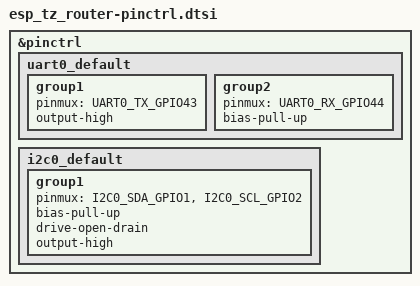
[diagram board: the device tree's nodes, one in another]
/*
 * Copyright (c) 2025 Espressif Systems (Shanghai) Co., Ltd.
 *
 * SPDX-License-Identifier: Apache-2.0
 */

#include <zephyr/dt-bindings/pinctrl/esp-pinctrl-common.h>
#include <dt-bindings/pinctrl/esp32s3-pinctrl.h>
#include <zephyr/dt-bindings/pinctrl/esp32s3-gpio-sigmap.h>

&pinctrl {
	uart0_default: uart0_default {
		group1 {
			pinmux = <UART0_TX_GPIO43>;
			output-high;
		};
		group2 {
			pinmux = <UART0_RX_GPIO44>;
			bias-pull-up;
		};
	};

	i2c0_default: i2c0_default {
		group1 {
			pinmux = <I2C0_SDA_GPIO1>,
				 <I2C0_SCL_GPIO2>;
			bias-pull-up;
			drive-open-drain;
			output-high;
		};
	};
};
